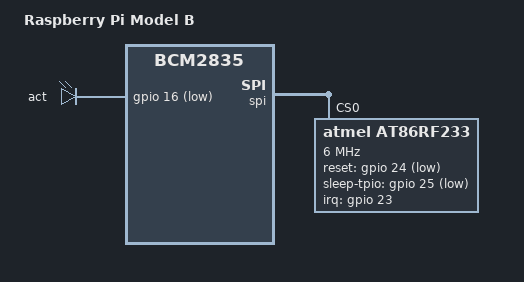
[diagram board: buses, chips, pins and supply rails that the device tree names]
/dts-v1/;
#include "bcm2835-rpi.dtsi"

/ {
	compatible = "raspberrypi,model-b", "brcm,bcm2835";
	model = "Raspberry Pi Model B";

	leds {
		act {
			gpios = <&gpio 16 1>;
		};
	};
};

&gpio {
	pinctrl-0 = <&gpioout &alt0 &alt3>;
};

&spi {
    status = "okay";
    at86rf233@0 {
        compatible = "atmel,at86rf233";
        spi-max-frequency = <6000000>;
        reg = <0>;
        interrupts = <23 4>;
        interrupt-parent = <&gpio>;
        reset-gpio = <&gpio 24 1>;
        sleep-tpio = <&gpio 25 1>;
        xtal-trim = /bits/ 8 <0x0F>;
    };
};
